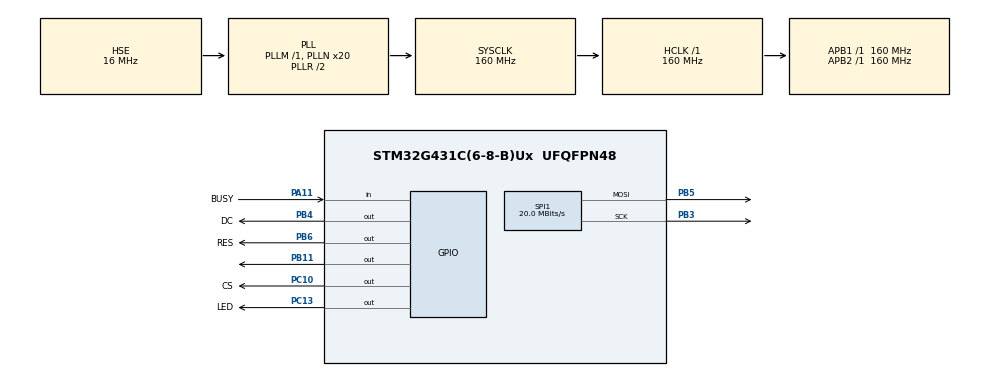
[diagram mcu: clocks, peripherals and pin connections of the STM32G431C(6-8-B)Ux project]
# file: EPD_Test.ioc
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Mcu.Family=STM32G4
Mcu.Name=STM32G431C(6-8-B)Ux
Mcu.Package=UFQFPN48
NVIC.PriorityGroup=NVIC_PRIORITYGROUP_4
PA11.GPIO_Label=BUSY
PA11.Signal=GPIO_Input
PA13.Mode=Serial_Wire
PA13.Signal=SYS_JTMS-SWDIO
PA14.Mode=Serial_Wire
PA14.Signal=SYS_JTCK-SWCLK
PB11.Signal=GPIO_Output
PB3.Mode=TX_Only_Simplex_Unidirect_Master
PB3.Signal=SPI1_SCK
PB4.GPIO_Label=DC
PB4.GPIO_ModeDefaultOutputPP=GPIO_MODE_OUTPUT_PP
PB4.GPIO_PuPd=GPIO_NOPULL
PB4.GPIO_Speed=GPIO_SPEED_FREQ_VERY_HIGH
PB4.PinState=GPIO_PIN_SET
PB4.Signal=GPIO_Output
PB5.Mode=TX_Only_Simplex_Unidirect_Master
PB5.Signal=SPI1_MOSI
PB6.GPIO_Label=RES
PB6.GPIO_ModeDefaultOutputPP=GPIO_MODE_OUTPUT_PP
PB6.GPIO_PuPd=GPIO_NOPULL
PB6.GPIO_Speed=GPIO_SPEED_FREQ_VERY_HIGH
PB6.PinState=GPIO_PIN_SET
PB6.Signal=GPIO_Output
PC10.GPIO_Label=CS
PC10.GPIO_ModeDefaultOutputPP=GPIO_MODE_OUTPUT_PP
PC10.GPIO_PuPd=GPIO_NOPULL
PC10.GPIO_Speed=GPIO_SPEED_FREQ_VERY_HIGH
PC10.PinState=GPIO_PIN_SET
PC10.Signal=GPIO_Output
PC13.GPIO_Label=LED
PC13.Signal=GPIO_Output
PF0-OSC_IN.Mode=HSE-External-Oscillator
PF0-OSC_IN.Signal=RCC_OSC_IN
PF1-OSC_OUT.Mode=HSE-External-Oscillator
PF1-OSC_OUT.Signal=RCC_OSC_OUT
ProjectManager.HeapSize=0x200
ProjectManager.StackSize=0x400
ProjectManager.TargetToolchain=MDK-ARM V5.32
RCC.ADC12Freq_Value=160000000
RCC.AHBFreq_Value=160000000
RCC.APB1Freq_Value=160000000
RCC.APB1TimFreq_Value=160000000
RCC.APB2Freq_Value=160000000
RCC.APB2TimFreq_Value=160000000
RCC.CortexFreq_Value=160000000
RCC.EXTERNAL_CLOCK_VALUE=12288000
RCC.EnbaleCSS=true
RCC.HCLKFreq_Value=160000000
RCC.HSE_VALUE=16000000
RCC.HSI48_VALUE=48000000
RCC.HSI_VALUE=16000000
RCC.LSE_VALUE=32768
RCC.PLLN=20
RCC.PLLSourceVirtual=RCC_PLLSOURCE_HSE
RCC.SYSCLKFreq_VALUE=160000000
RCC.SYSCLKSource=RCC_SYSCLKSOURCE_PLLCLK
RCC.USBFreq_Value=160000000
RCC.VCOOutputFreq_Value=320000000
SPI1.BaudRatePrescaler=SPI_BAUDRATEPRESCALER_8
SPI1.CLKPhase=SPI_PHASE_1EDGE
SPI1.CLKPolarity=SPI_POLARITY_LOW
SPI1.CalculateBaudRate=20.0 MBits/s
SPI1.DataSize=SPI_DATASIZE_8BIT
SPI1.Direction=SPI_DIRECTION_2LINES
SPI1.Mode=SPI_MODE_MASTER
SPI1.VirtualType=VM_MASTER
VP_SYS_VS_DBSignals.Mode=DisableDeadBatterySignals
board=custom

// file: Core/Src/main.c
/* USER CODE BEGIN Header */
/**
  ******************************************************************************
  * @file           : main.c
  * @brief          : Main program body
  ******************************************************************************
  * @attention
  *
  * Copyright (c) 2024 STMicroelectronics.
  * All rights reserved.
  *
  * This software is licensed under terms that can be found in the LICENSE file
  * in the root directory of this software component.
  * If no LICENSE file comes with this software, it is provided AS-IS.
  *
  ******************************************************************************
  */
/* USER CODE END Header */
#include "main.h"
#include "spi.h"
#include "gpio.h"

/* USER CODE BEGIN Includes */
#include "Delay.h"
#include "EPD_HW.h"
#include "EPD_SW.h"
/* USER CODE END Includes */

void SystemClock_Config(void);

int main(void)
{

  /* MCU Configuration--------------------------------------------------------*/

  /* Reset of all peripherals, Initializes the Flash interface and the Systick. */
  HAL_Init();

  /* Configure the system clock */
  SystemClock_Config();

  /* Initialize all configured peripherals */
  MX_GPIO_Init();
  MX_SPI1_Init();
  /* USER CODE BEGIN 2 */

	HAL_GPIO_WritePin(GPIOC,GPIO_PIN_13,0);
	Delay_ms(50);
	HAL_GPIO_WritePin(GPIOC,GPIO_PIN_13,1);
	Delay_ms(50);
	HAL_GPIO_WritePin(GPIOC,GPIO_PIN_13,0);
	Delay_ms(50);
	HAL_GPIO_WritePin(GPIOC,GPIO_PIN_13,1);
	Delay_ms(50);

	EPD_Inf.WEIGHT_MAX = 296;
	EPD_Inf.HEIGHT_MAX = 152;

	EPD_Inf.StateDC = DATA;
	EPD_Inf.IsSleep = 0;
	EPD_Inf.ErrorFalg = 0;
	EPD_Inf.IsSelect = 0;
	EPD_Inf.NeedUpdate = 0;

	EPD_Init();
	UI_Init();
	EPD_Display_Clear();

	UI_DrawBox_EMPTY(0,25,100,50,BLACK,WHITE,2);
	UI_DrawBox_EMPTY(110,0,210,50,BLACK,RED,2);
	UI_DrawBox_EMPTY(110,100,210,150,RED,WHITE,2);

	UI_Update_All();

	UI_DrawBox_FILLED(0,0,60,60,BLACK);

	//UI_Update_Part(0,0,60,60);//unusable for 3colors EPD

  while (1)
  {
		HAL_GPIO_WritePin(GPIOC,GPIO_PIN_13,0);
		Delay_ms(200);
		HAL_GPIO_WritePin(GPIOC,GPIO_PIN_13,1);
		Delay_ms(200);

    /* USER CODE END WHILE */

  }
}

void SystemClock_Config(void)
{
  RCC_OscInitTypeDef RCC_OscInitStruct = {0};
  RCC_ClkInitTypeDef RCC_ClkInitStruct = {0};

  /** Configure the main internal regulator output voltage
  */
  HAL_PWREx_ControlVoltageScaling(PWR_REGULATOR_VOLTAGE_SCALE1_BOOST);

  /** Initializes the RCC Oscillators according to the specified parameters
  * in the RCC_OscInitTypeDef structure.
  */
  RCC_OscInitStruct.OscillatorType = RCC_OSCILLATORTYPE_HSE;
  RCC_OscInitStruct.HSEState = RCC_HSE_ON;
  RCC_OscInitStruct.PLL.PLLState = RCC_PLL_ON;
  RCC_OscInitStruct.PLL.PLLSource = RCC_PLLSOURCE_HSE;
  RCC_OscInitStruct.PLL.PLLM = RCC_PLLM_DIV1;
  RCC_OscInitStruct.PLL.PLLN = 20;
  RCC_OscInitStruct.PLL.PLLP = RCC_PLLP_DIV2;
  RCC_OscInitStruct.PLL.PLLQ = RCC_PLLQ_DIV2;
  RCC_OscInitStruct.PLL.PLLR = RCC_PLLR_DIV2;
  if (HAL_RCC_OscConfig(&RCC_OscInitStruct) != HAL_OK)
  {
    Error_Handler();
  }

  /** Initializes the CPU, AHB and APB buses clocks
  */
  RCC_ClkInitStruct.ClockType = RCC_CLOCKTYPE_HCLK|RCC_CLOCKTYPE_SYSCLK
                              |RCC_CLOCKTYPE_PCLK1|RCC_CLOCKTYPE_PCLK2;
  RCC_ClkInitStruct.SYSCLKSource = RCC_SYSCLKSOURCE_PLLCLK;
  RCC_ClkInitStruct.AHBCLKDivider = RCC_SYSCLK_DIV1;
  RCC_ClkInitStruct.APB1CLKDivider = RCC_HCLK_DIV1;
  RCC_ClkInitStruct.APB2CLKDivider = RCC_HCLK_DIV1;

  if (HAL_RCC_ClockConfig(&RCC_ClkInitStruct, FLASH_LATENCY_4) != HAL_OK)
  {
    Error_Handler();
  }

  /** Enables the Clock Security System
  */
  HAL_RCC_EnableCSS();
}

void Error_Handler(void)
{
  __disable_irq();
  while (1)
  {
  }
}
